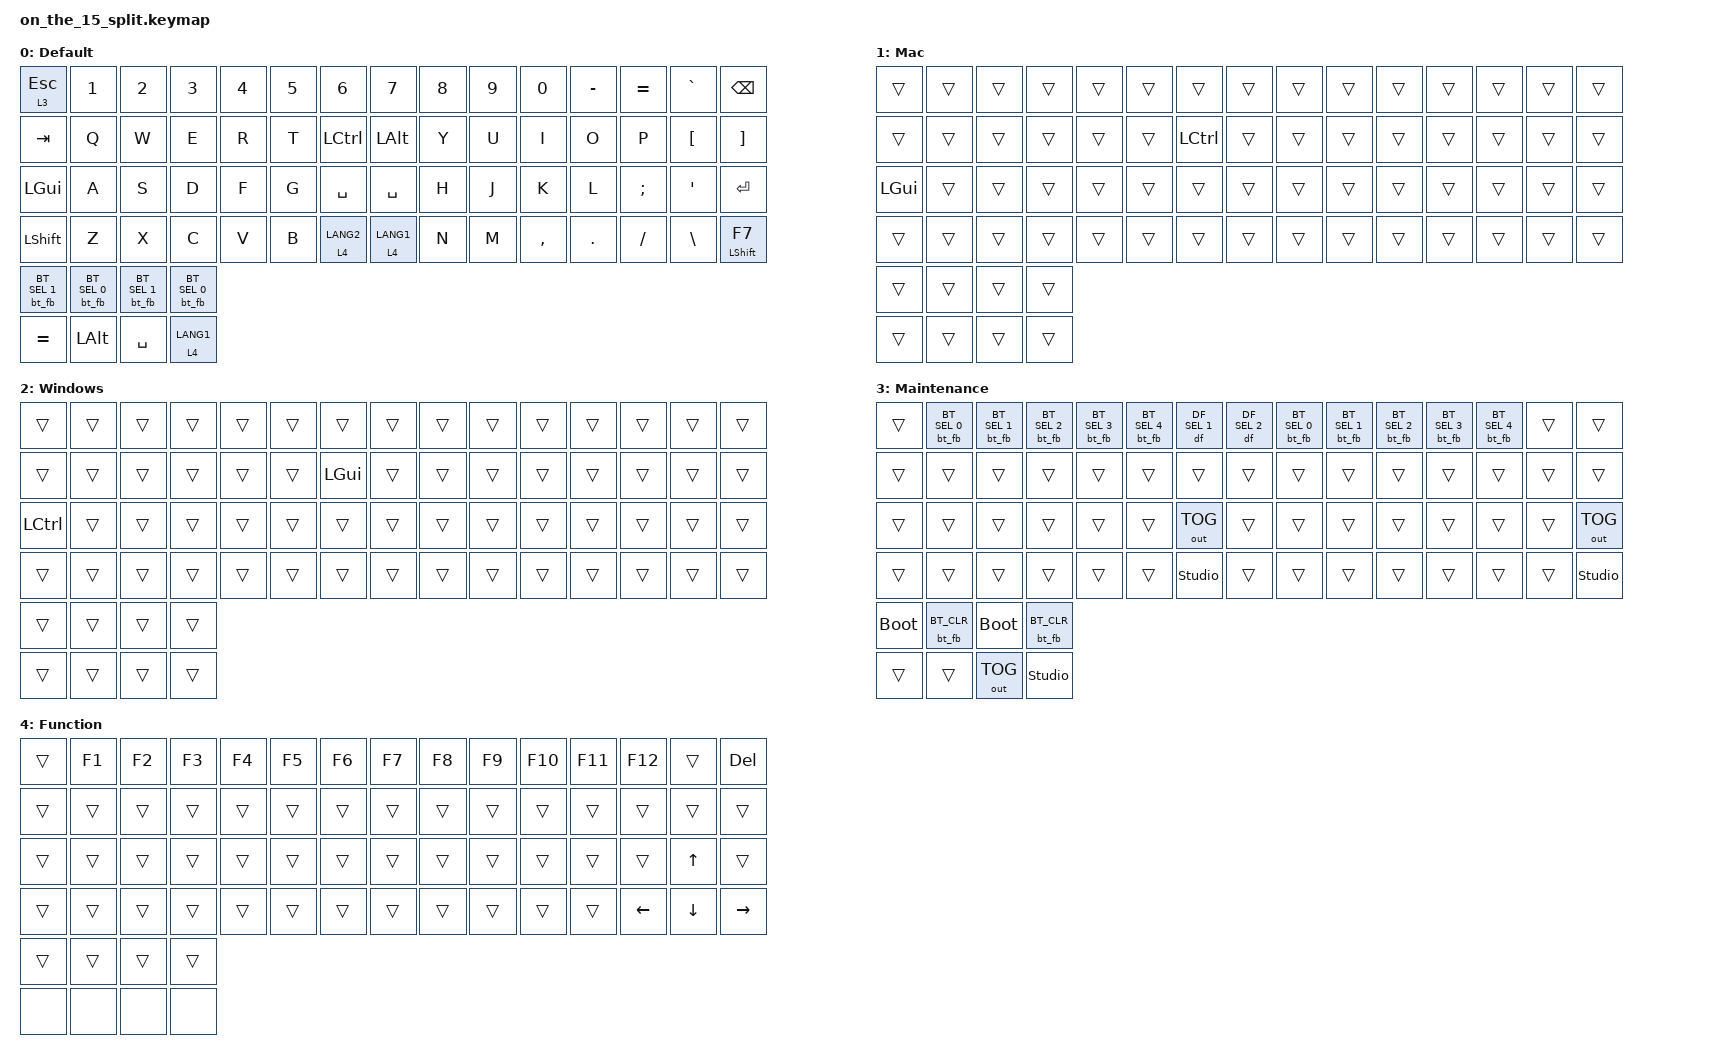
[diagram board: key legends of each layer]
/* Personal split trial: endpoint-specific Mac/Windows default layers. */

#include <behaviors.dtsi>
#include <behaviors/default_layer.dtsi>
#include <dt-bindings/zmk/bt.h>
#include <dt-bindings/zmk/keys.h>
#include <dt-bindings/zmk/outputs.h>
#include <dt-bindings/zmk_behavior_default_layer/default_layer.h>

/ {
    behaviors {
        bt_fb: bluetooth_feedback {
            compatible = "onthe15,behavior-bt-feedback";
            #binding-cells = <2>;
            display-name = "Bluetooth Feedback";
        };
    };

    keymap {
        compatible = "zmk,keymap";

        /*
         * 68 bindings per layer: the 64 of the x7/x8 layout followed by the
         * four keys only an x8 half carries, which the position map places at
         * 64 through 67. The visual rows are the 15 of the x7/x8 transform,
         * then the four side switches, then those four extension keys.
         */
        default_layer {
            display-name = "Default";
            bindings = <
&lt 3 ESC &kp N1 &kp N2 &kp N3 &kp N4 &kp N5 &kp N6  &kp N7 &kp N8 &kp N9 &kp N0 &kp MINUS &kp EQUAL &kp GRAVE &kp BSPC
&kp TAB &kp Q &kp W &kp E &kp R &kp T &kp LCTRL  &kp LALT &kp Y &kp U &kp I &kp O &kp P &kp LBKT &kp RBKT
&kp LGUI &kp A &kp S &kp D &kp F &kp G &kp SPACE  &kp SPACE &kp H &kp J &kp K &kp L &kp SEMI &kp SQT &kp ENTER
&kp LSHFT &kp Z &kp X &kp C &kp V &kp B &lt 4 LANG2  &lt 4 LANG1 &kp N &kp M &kp COMMA &kp DOT &kp FSLH &kp BSLH &mt LSHFT F7
&bt_fb BT_SEL 1 &bt_fb BT_SEL 0 &bt_fb BT_SEL 1 &bt_fb BT_SEL 0
&kp EQUAL &kp LALT &kp SPACE &lt 4 LANG1
            >;
        };

        mac_layer {
            display-name = "Mac";
            bindings = <
&trans &trans &trans &trans &trans &trans &trans  &trans &trans &trans &trans &trans &trans &trans &trans
&trans &trans &trans &trans &trans &trans &kp LCTRL  &trans &trans &trans &trans &trans &trans &trans &trans
&kp LGUI &trans &trans &trans &trans &trans &trans  &trans &trans &trans &trans &trans &trans &trans &trans
&trans &trans &trans &trans &trans &trans &trans  &trans &trans &trans &trans &trans &trans &trans &trans
&trans &trans &trans &trans
&trans &trans &trans &trans
            >;
        };

        windows_layer {
            display-name = "Windows";
            bindings = <
&trans &trans &trans &trans &trans &trans &trans  &trans &trans &trans &trans &trans &trans &trans &trans
&trans &trans &trans &trans &trans &trans &kp LGUI  &trans &trans &trans &trans &trans &trans &trans &trans
&kp LCTRL &trans &trans &trans &trans &trans &trans  &trans &trans &trans &trans &trans &trans &trans &trans
&trans &trans &trans &trans &trans &trans &trans  &trans &trans &trans &trans &trans &trans &trans &trans
&trans &trans &trans &trans
&trans &trans &trans &trans
            >;
        };

        maintenance_layer: maintenance_layer {
            display-name = "Maintenance";
            bindings = <
&trans &bt_fb BT_SEL 0 &bt_fb BT_SEL 1 &bt_fb BT_SEL 2 &bt_fb BT_SEL 3 &bt_fb BT_SEL 4 &df DF_SEL 1  &df DF_SEL 2 &bt_fb BT_SEL 0 &bt_fb BT_SEL 1 &bt_fb BT_SEL 2 &bt_fb BT_SEL 3 &bt_fb BT_SEL 4 &trans &trans
&trans &trans &trans &trans &trans &trans &trans  &trans &trans &trans &trans &trans &trans &trans &trans
&trans &trans &trans &trans &trans &trans &out OUT_TOG  &trans &trans &trans &trans &trans &trans &trans &out OUT_TOG
&trans &trans &trans &trans &trans &trans &studio_unlock  &trans &trans &trans &trans &trans &trans &trans &studio_unlock
&bootloader &bt_fb BT_CLR &bootloader &bt_fb BT_CLR
&trans &trans &out OUT_TOG &studio_unlock
            >;
        };

        function_layer {
            display-name = "Function";
            bindings = <
&trans &kp F1 &kp F2 &kp F3 &kp F4 &kp F5 &kp F6  &kp F7 &kp F8 &kp F9 &kp F10 &kp F11 &kp F12 &trans &kp DEL
&trans &trans &trans &trans &trans &trans &trans  &trans &trans &trans &trans &trans &trans &trans &trans
&trans &trans &trans &trans &trans &trans &trans  &trans &trans &trans &trans &trans &trans &kp UP &trans
&trans &trans &trans &trans &trans &trans &trans  &trans &trans &trans &trans &trans &kp LEFT &kp DOWN &kp RIGHT
&trans &trans &trans &trans
&none &none &none &none
            >;
        };
    };
};
